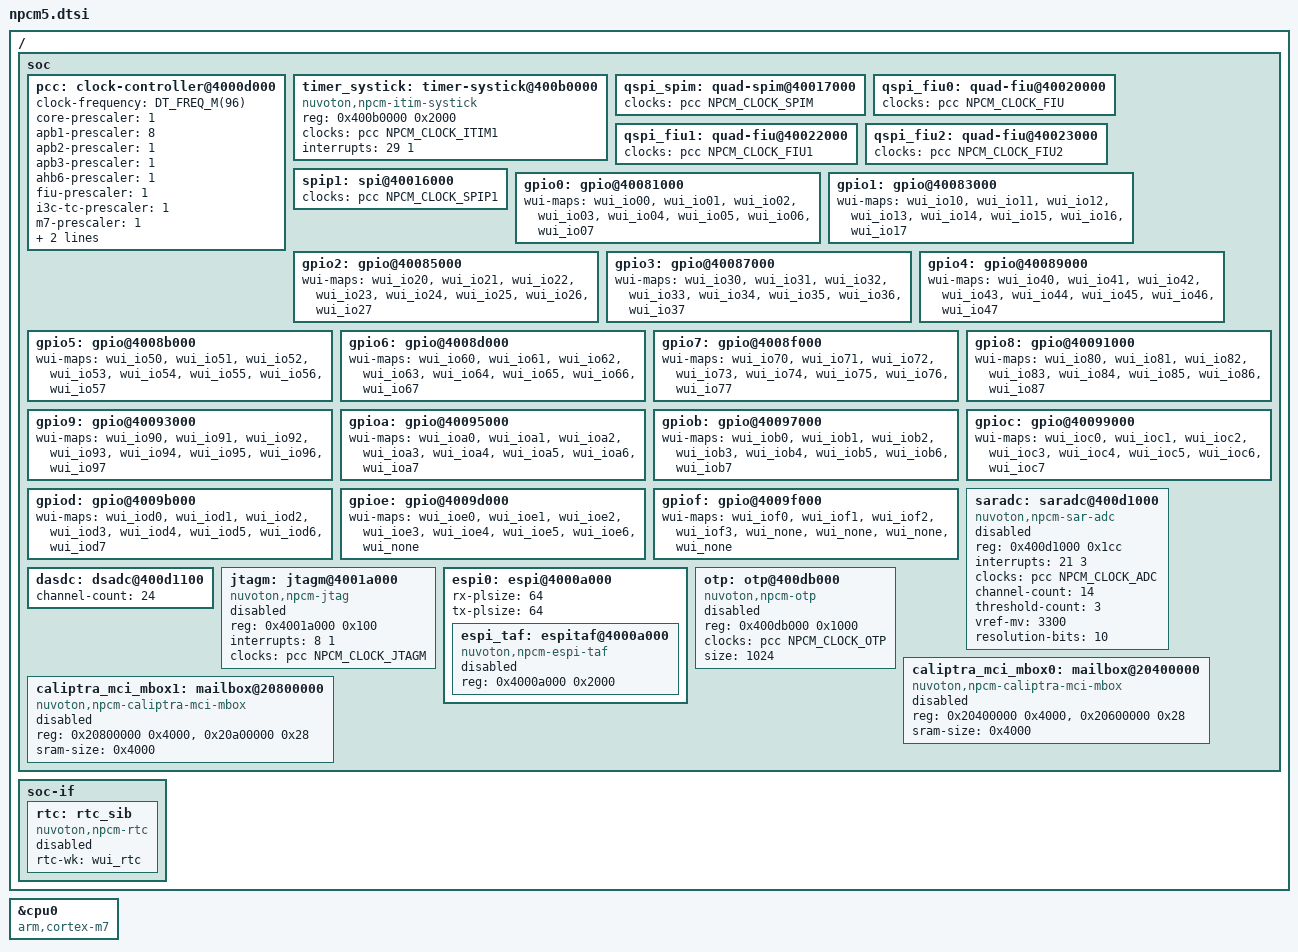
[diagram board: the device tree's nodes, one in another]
/*
 * Copyright (c) 2024 Nuvoton Technology Corporation.
 *
 * SPDX-License-Identifier: Apache-2.0
 */

/* npcm5 series mapping table between MIWU wui bits and source device */
#include "npcm5/npcm5-miwus-wui-map.dtsi"
/* npcm5 series mapping table between MIWU groups and interrupts */
#include "npcm5/npcm5-miwus-int-map.dtsi"
/* npcm5 series eSPI VW mapping table */
#include "npcm5/npcm5-espi-vws-map.dtsi"

/* Device tree declarations of npcm soc family */
#include "npcm.dtsi"
#include "npcm5/npcm5-pincfg-default.dtsi"
#include "npcm5/npcm5-pinctrl.dtsi"
/* eSPI Virtual Wire GPIO controller (disabled by default) */
#include "npcm-vw-gpio.dtsi"
#include <freq.h>

/ {
	soc {
		pcc: clock-controller@4000d000 {
			clock-frequency = <DT_FREQ_M(96)>; /* OFMCLK runs at 96MHz */
			core-prescaler = <1>; /* CORE_CLK runs at 96MHz */
			apb1-prescaler = <8>; /* APB1_CLK runs at 12MHz */
			apb2-prescaler = <1>; /* APB2_CLK runs at 96MHz */
			apb3-prescaler = <1>; /* APB3_CLK runs at 96MHz */
			ahb6-prescaler = <1>; /* AHB6_CLK runs at 96MHz */
			fiu-prescaler = <1>; /* FIU_CLK runs at 96MHz */
			i3c-tc-prescaler = <1>; /* I3C_TC_CLK runs at 96MHz */
			m7-prescaler = <1>; /* M7_FCLK runs at 96MHz */
			mram-prescaler = <2>; /* MRAM_CLK runs at 48MHz */
			css-prescaler = <2>; /* CSS_FCLK runs at 48MHz */
		};

		timer_systick: timer-systick@400b0000 {
			compatible = "nuvoton,npcm-itim-systick";
			#address-cells = <1>;
			#size-cells = <0>;
			reg = <0x400b0000 0x2000>;
			clocks = <&pcc NPCM_CLOCK_ITIM1>;
			interrupts = <29 1>;
		};

		qspi_spim: quad-spim@40017000 {
			clocks = <&pcc NPCM_CLOCK_SPIM>;
		};

		qspi_fiu0: quad-fiu@40020000 {
			clocks = <&pcc NPCM_CLOCK_FIU>;
		};

		qspi_fiu1: quad-fiu@40022000 {
			clocks = <&pcc NPCM_CLOCK_FIU1>;
		};

		qspi_fiu2: quad-fiu@40023000 {
			clocks = <&pcc NPCM_CLOCK_FIU2>;
		};

		spip1: spi@40016000 {
			clocks = <&pcc NPCM_CLOCK_SPIP1>;
		};

		gpio0: gpio@40081000 {
			wui-maps = <&wui_io00 &wui_io01 &wui_io02 &wui_io03
				    &wui_io04 &wui_io05 &wui_io06 &wui_io07>;
		};

		gpio1: gpio@40083000 {
			wui-maps = <&wui_io10 &wui_io11 &wui_io12 &wui_io13
				    &wui_io14 &wui_io15 &wui_io16 &wui_io17>;
		};

		gpio2: gpio@40085000 {
			wui-maps = <&wui_io20 &wui_io21 &wui_io22 &wui_io23
				    &wui_io24 &wui_io25 &wui_io26 &wui_io27>;
		};

		gpio3: gpio@40087000 {
			wui-maps = <&wui_io30 &wui_io31 &wui_io32 &wui_io33
				    &wui_io34 &wui_io35 &wui_io36 &wui_io37>;
		};

		gpio4: gpio@40089000 {
			wui-maps = <&wui_io40 &wui_io41 &wui_io42 &wui_io43
				    &wui_io44 &wui_io45 &wui_io46 &wui_io47>;
		};

		gpio5: gpio@4008b000 {
			wui-maps = <&wui_io50 &wui_io51 &wui_io52 &wui_io53
				    &wui_io54 &wui_io55 &wui_io56 &wui_io57>;
		};

		gpio6: gpio@4008d000 {
			wui-maps = <&wui_io60 &wui_io61 &wui_io62 &wui_io63
				    &wui_io64 &wui_io65 &wui_io66 &wui_io67>;
		};

		gpio7: gpio@4008f000 {
			wui-maps = <&wui_io70 &wui_io71 &wui_io72 &wui_io73
				    &wui_io74 &wui_io75 &wui_io76 &wui_io77>;
		};

		gpio8: gpio@40091000 {
			wui-maps = <&wui_io80 &wui_io81 &wui_io82 &wui_io83
				    &wui_io84 &wui_io85 &wui_io86 &wui_io87>;
		};

		gpio9: gpio@40093000 {
			wui-maps = <&wui_io90 &wui_io91 &wui_io92 &wui_io93
				    &wui_io94 &wui_io95 &wui_io96 &wui_io97>;
		};

		gpioa: gpio@40095000 {
			wui-maps = <&wui_ioa0 &wui_ioa1 &wui_ioa2 &wui_ioa3
				    &wui_ioa4 &wui_ioa5 &wui_ioa6 &wui_ioa7>;
		};

		gpiob: gpio@40097000 {
			wui-maps = <&wui_iob0 &wui_iob1 &wui_iob2 &wui_iob3
				    &wui_iob4 &wui_iob5 &wui_iob6 &wui_iob7>;
		};

		gpioc: gpio@40099000 {
			wui-maps = <&wui_ioc0 &wui_ioc1 &wui_ioc2 &wui_ioc3
				    &wui_ioc4 &wui_ioc5 &wui_ioc6 &wui_ioc7>;
		};

		gpiod: gpio@4009b000 {
			wui-maps = <&wui_iod0 &wui_iod1 &wui_iod2 &wui_iod3
				    &wui_iod4 &wui_iod5 &wui_iod6 &wui_iod7>;
		};

		gpioe: gpio@4009d000 {
			wui-maps = <&wui_ioe0 &wui_ioe1 &wui_ioe2 &wui_ioe3
				    &wui_ioe4 &wui_ioe5 &wui_ioe6 &wui_none>;
		};

		gpiof: gpio@4009f000 {
			wui-maps = <&wui_iof0 &wui_iof1 &wui_iof2 &wui_iof3
				    &wui_none &wui_none &wui_none &wui_none>;
		};

		saradc: saradc@400d1000 {
			compatible = "nuvoton,npcm-sar-adc";
			/* 0x1C8: last reg ADCTD7-6PO at offset 0x1C6 (4 pairs for 8 temp channels) */
			reg = <0x400d1000 0x1cc>;
			interrupts = <21 3>;
			clocks = <&pcc NPCM_CLOCK_ADC>;
			/* ADCCS supports CC0-CC13 only (14 channels per datasheet) */
			channel-count = <14>;
			threshold-count = <3>;
			vref-mv = <3300>;
			resolution-bits = <10>;
			#io-channel-cells = <1>;
			status = "disabled";
		};

		dasdc: dsadc@400d1100 {
			channel-count = <24>;
		};

		jtagm: jtagm@4001a000 {
			compatible = "nuvoton,npcm-jtag";
			reg = <0x4001a000 0x100>;
			interrupts = <8 1>;
			clocks = <&pcc NPCM_CLOCK_JTAGM>;
			status = "disabled";
		};

		espi0: espi@4000a000 {
			rx-plsize = <64>;
			tx-plsize = <64>;

			espi_taf: espitaf@4000a000 {
				compatible = "nuvoton,npcm-espi-taf";
				reg = <0x4000a000 0x2000>;
				status = "disabled";
			};
		};

		otp: otp@400db000 {
			compatible = "nuvoton,npcm-otp";
			reg = <0x400db000 0x1000>;
			clocks = <&pcc NPCM_CLOCK_OTP>;
			size = <1024>;
			status = "disabled";
		};

		/*
		 * Caliptra MCI mailboxes (MCU_MBOX0/1), M7-side view: a 16 KB
		 * SRAM aperture, and its CSR page 0x200000 above it. A1 does
		 * not route soc_mcu_mbox*_data_avail to the M7, so the
		 * interrupts live in the A2 board revision overlay.
		 */
		caliptra_mci_mbox0: mailbox@20400000 {
			compatible = "nuvoton,npcm-caliptra-mci-mbox";
			reg = <0x20400000 0x4000>, <0x20600000 0x28>;
			reg-names = "sram", "csr";
			sram-size = <0x4000>;
			#mbox-cells = <1>;
			status = "disabled";
		};

		caliptra_mci_mbox1: mailbox@20800000 {
			compatible = "nuvoton,npcm-caliptra-mci-mbox";
			reg = <0x20800000 0x4000>, <0x20a00000 0x28>;
			reg-names = "sram", "csr";
			sram-size = <0x4000>;
			#mbox-cells = <1>;
			status = "disabled";
		};

		/*
		 * NPCM5 has no PWM_A module (PWDWN_CTL[2] bit 0 is repurposed by
		 * JTAGM), so there is intentionally no pwm1/pwm@40080000 node.
		 */
	};

	soc-if {
		/* Soc specific peripheral interface phandles which don't contain
		 * 'reg' prop. Please overwrite 'status' prop. to 'okay' if you
		 * want to switch the interface from io to specific peripheral.
		 */
		rtc: rtc_sib{
			compatible = "nuvoton,npcm-rtc";
			rtc-wk = <&wui_rtc>;
			status = "disabled";
		};
	};
};

/* NPCM5 is Cortex-M7; npcm.dtsi defaults cpu0 to M4 for the NPCM4 series. */
&cpu0 {
	compatible = "arm,cortex-m7";
};
